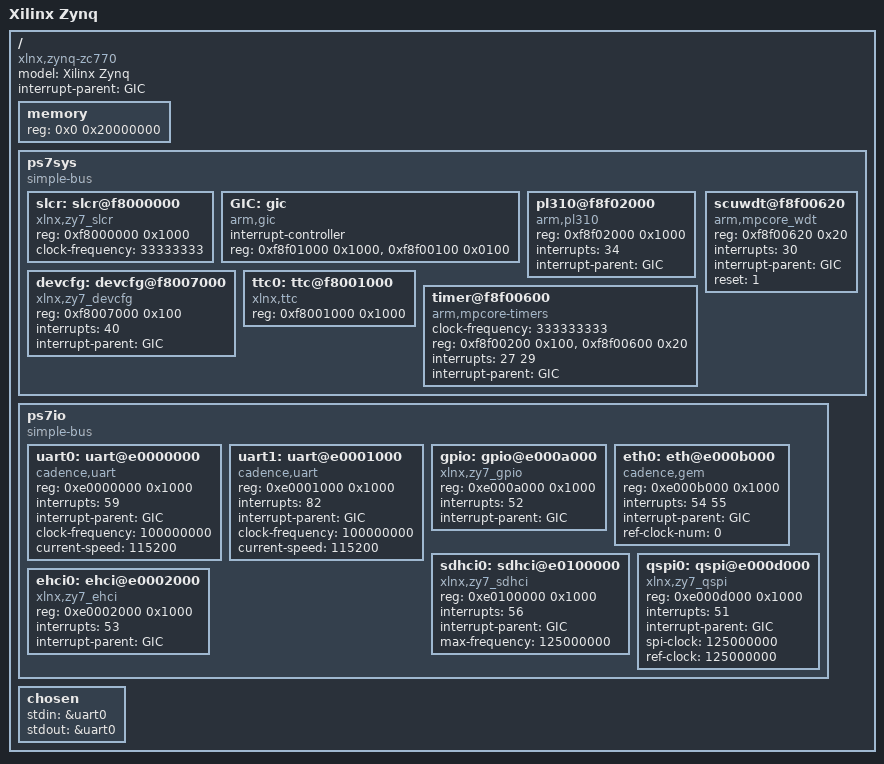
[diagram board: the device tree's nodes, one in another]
/*-
 * Copyright (c) 2015 Maksym Sobolyev <sobomax@FreeBSD.org>
 * All rights reserved.
 *
 * Redistribution and use in source and binary forms, with or without
 * modification, are permitted provided that the following conditions
 * are met:
 * 1. Redistributions of source code must retain the above copyright
 *    notice, this list of conditions and the following disclaimer.
 * 2. Redistributions in binary form must reproduce the above copyright
 *    notice, this list of conditions and the following disclaimer in the
 *    documentation and/or other materials provided with the distribution.
 *
 * THIS SOFTWARE IS PROVIDED BY THE AUTHOR AND CONTRIBUTORS ``AS IS'' AND
 * ANY EXPRESS OR IMPLIED WARRANTIES, INCLUDING, BUT NOT LIMITED TO, THE
 * IMPLIED WARRANTIES OF MERCHANTABILITY AND FITNESS FOR A PARTICULAR PURPOSE
 * ARE DISCLAIMED. IN NO EVENT SHALL THE AUTHOR OR CONTRIBUTORS BE LIABLE
 * FOR ANY DIRECT, INDIRECT, INCIDENTAL, SPECIAL, EXEMPLARY, OR CONSEQUENTIAL
 * DAMAGES (INCLUDING, BUT NOT LIMITED TO, PROCUREMENT OF SUBSTITUTE GOODS
 * OR SERVICES; LOSS OF USE, DATA, OR PROFITS; OR BUSINESS INTERRUPTION)
 * HOWEVER CAUSED AND ON ANY THEORY OF LIABILITY, WHETHER IN CONTRACT, STRICT
 * LIABILITY, OR TORT (INCLUDING NEGLIGENCE OR OTHERWISE) ARISING IN ANY WAY
 * OUT OF THE USE OF THIS SOFTWARE, EVEN IF ADVISED OF THE POSSIBILITY OF
 * SUCH DAMAGE.
 * 
 * $FreeBSD$
 */

/dts-v1/;

/ {
	model = "Xilinx Zynq";
	compatible = "xlnx,zynq-zc770", "xlnx,zynq-7000";
	#address-cells = <1>;
	#size-cells = <1>;
	interrupt-parent = <&GIC>;

	// cpus {
	//	#address-cells = <1>;
	//	#size-cells = <0>;
	//	cpu@0 {
	//		device-type = "cpu";
	//		model = "ARM Cortex-A9";
	//	};
	// };

	memory {
		// First megabyte isn't accessible by all interconnect masters.
		device_type = "memory";
		reg = <0x0 0x20000000>;	/* 512MB RAM at 0x0 */
	};

	// Zynq PS System registers.
	//
 	ps7sys {
		device_type = "soc";
		compatible = "simple-bus";
		#address-cells = <1>;
		#size-cells = <1>;
		ranges ;

		// SLCR block
		slcr: slcr@f8000000 {
			compatible = "xlnx,zy7_slcr";
			reg = <0xf8000000 0x1000>;
			clock-frequency = <33333333>; // 33Mhz PS_CLK
		};

		// Interrupt controller
		GIC: gic {
			compatible = "arm,gic";
			interrupt-controller;
			#address-cells = <0>;
			#interrupt-cells = <1>;
			reg = <0xf8f01000 0x1000>, // distributer registers
			      <0xf8f00100 0x0100>; // CPU if registers
		};

		// L2 cache controller
		pl310@f8f02000 {
			compatible = "arm,pl310";
			reg = <0xf8f02000 0x1000>;
			interrupts = < 34 >;
			interrupt-parent = <&GIC>;
		};

		// Device Config
		devcfg: devcfg@f8007000 {
			compatible = "xlnx,zy7_devcfg";
			reg = <0xf8007000 0x100>;
			interrupts = < 40 >;
			interrupt-parent = <&GIC>;
		};

		// triple timer counter0
		ttc0: ttc@f8001000 {
		 	compatible = "xlnx,ttc";
			reg = <0xf8001000 0x1000>;
		};

                // ARM Cortex A9 TWD Timer
                timer@f8f00600 {
                        compatible = "arm,mpcore-timers";
                        clock-frequency = <333333333>; // 333Mhz
                        #address-cells = <1>;
                        #size-cells = <0>;
                        reg = <0xf8f00200 0x100>, // Global Timer Regs
                              <0xf8f00600 0x20>;  // Private Timer Regs
                        interrupts = < 27 29 >;
                        interrupt-parent = <&GIC>;
                };

		scuwdt@f8f00620 {
		 	device_type = "watchdog";
		 	compatible = "arm,mpcore_wdt";
		 	reg = <0xf8f00620 0x20>;
		 	interrupts = < 30 >;
		 	interrupt-parent = <&GIC>;
		 	reset = <1>;
		};
	}; // pssys@f8000000

	// Zynq PS I/O Peripheral registers.
	//
	ps7io {
		device_type = "soc";
		compatible = "simple-bus";
		#address-cells = <1>;
		#size-cells = <1>;
		ranges ;

		uart0: uart@e0000000 {
			device_type = "serial";
			compatible = "cadence,uart";
			reg = <0xe0000000 0x1000>;
			interrupts = < 59 >;
			interrupt-parent = <&GIC>;
			clock-frequency = < 100000000 >;
			current-speed = <115200>;
		};

                uart1: uart@e0001000 {
                        device_type = "serial";
                        compatible = "cadence,uart";
                        reg = <0xe0001000 0x1000>;
                        interrupts = < 82 >;
                        interrupt-parent = <&GIC>;
                        clock-frequency = < 100000000 >;
                        current-speed = <115200>;
                };

		gpio: gpio@e000a000 {
			compatible = "xlnx,zy7_gpio";
			reg = <0xe000a000 0x1000>;
		 	interrupts = < 52 >;
		 	interrupt-parent = <&GIC>;
		};

		// GigE
		eth0: eth@e000b000 {
		        // device_type = "network";

		 	compatible = "cadence,gem";
		 	reg = <0xe000b000 0x1000>;
			interrupts = < 54 55 >;
			interrupt-parent = <&GIC>;
			ref-clock-num = <0>;
		};

		// SDIO
		sdhci0: sdhci@e0100000 {
			compatible = "xlnx,zy7_sdhci";
			reg = <0xe0100000 0x1000>;
			interrupts = < 56 >;
			interrupt-parent = <&GIC>;
			max-frequency = <125000000>;
		};

		// QSPI
		qspi0: qspi@e000d000 {
			compatible = "xlnx,zy7_qspi";
			reg = <0xe000d000 0x1000>;
			interrupts = < 51 >;
			interrupt-parent = <&GIC>;
			spi-clock = <125000000>;
			ref-clock = <125000000>;
		};

		// USB
		ehci0: ehci@e0002000 {
			compatible = "xlnx,zy7_ehci";
			reg = <0xe0002000 0x1000>;
			interrupts = < 53 >;
			interrupt-parent = <&GIC>;
			//phy_vbus_ext;
		};

	}; // ps7io@e0000000

	chosen {
		stdin = &uart0;
		stdout = &uart0;
	};
};

